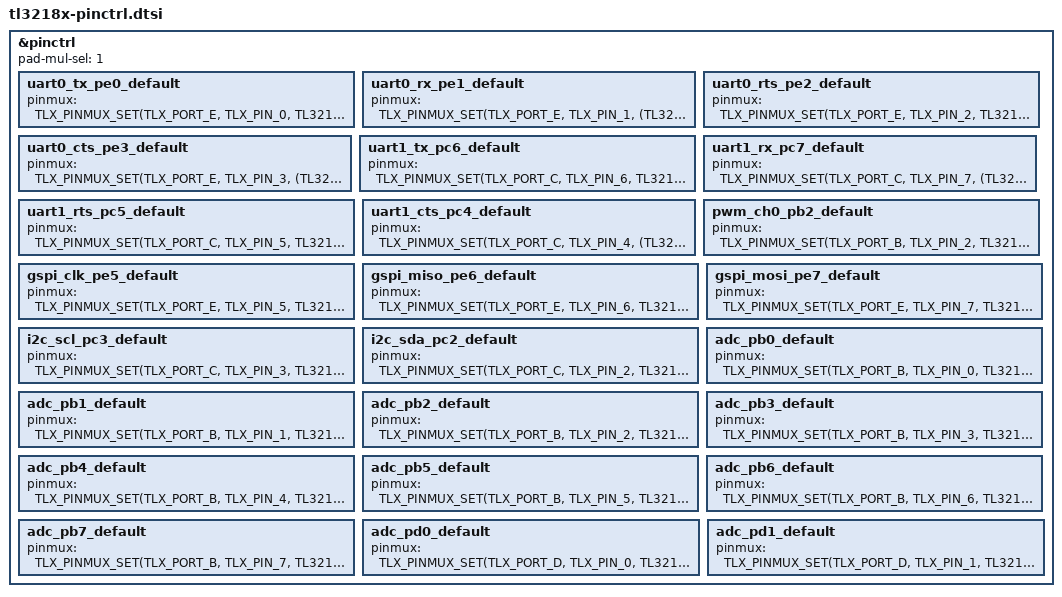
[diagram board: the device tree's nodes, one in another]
/*
 * Copyright (c) 2024 Telink Semiconductor
 *
 * SPDX-License-Identifier: Apache-2.0
 */

#include <zephyr/dt-bindings/pinctrl/tl321x-pinctrl.h>

&pinctrl {
	/* Set pad-mul-sel register value.
	 * Note: Pins functions below (pinmux = <...>) depend on this value.
	 */
	pad-mul-sel = <1>;

	/* UART0: TX(PE0), RX(PE1), RTS(PE2), CTS(PE3) */

	uart0_tx_pe0_default: uart0_tx_pe0_default {
		pinmux = <TLX_PINMUX_SET(TLX_PORT_E, TLX_PIN_0, TL321X_FUNC_UART0_TX)>;
	};
	uart0_rx_pe1_default: uart0_rx_pe1_default {
		pinmux = <TLX_PINMUX_SET(TLX_PORT_E, TLX_PIN_1,
				(TL321X_FUNC_UART0_RTX_IO | TL321X_PULL_UP))>;
	};
	uart0_rts_pe2_default: uart0_rts_pe2_default {
		pinmux = <TLX_PINMUX_SET(TLX_PORT_E, TLX_PIN_2, TL321X_FUNC_UART0_RTS)>;
	};
	uart0_cts_pe3_default: uart0_cts_pe3_default {
		pinmux = <TLX_PINMUX_SET(TLX_PORT_E, TLX_PIN_3,
				(TL321X_FUNC_UART0_CTS_I | TL321X_PULL_UP))>;
	};

	/* UART1: TX(PC6), RX(PC7), RTS(PC5), CTS(PC4) */

	uart1_tx_pc6_default: uart1_tx_pc6_default {
		pinmux = <TLX_PINMUX_SET(TLX_PORT_C, TLX_PIN_6, TL321X_FUNC_UART1_TX)>;
	};
	uart1_rx_pc7_default: uart1_rx_pc7_default {
		pinmux = <TLX_PINMUX_SET(TLX_PORT_C, TLX_PIN_7,
				(TL321X_FUNC_UART1_RTX_IO | TL321X_PULL_UP))>;
	};
	uart1_rts_pc5_default: uart1_rts_pc5_default {
		pinmux = <TLX_PINMUX_SET(TLX_PORT_C, TLX_PIN_5, TL321X_FUNC_UART1_RTS)>;
	};
	uart1_cts_pc4_default: uart1_cts_pc4_default {
		pinmux = <TLX_PINMUX_SET(TLX_PORT_C, TLX_PIN_4,
				(TL321X_FUNC_UART1_CTS_I | TL321X_PULL_UP))>;
	};

	/* PWM Channel 0 (PE4) */

	pwm_ch0_pb2_default: pwm_ch0_pb2_default {
		pinmux = <TLX_PINMUX_SET(TLX_PORT_B, TLX_PIN_2, TL321X_FUNC_PWM0)>;
	};

	/* Note:TL321X only supports gspi!!!*/
	/* GSPI: CLK(PE5), MISO(PE6), MOSI(PE7) */

	gspi_clk_pe5_default: gspi_clk_pe5_default {
		pinmux = <TLX_PINMUX_SET(TLX_PORT_E, TLX_PIN_5, TL321X_FUNC_GSPI_CK_IO)>;
	};
	gspi_miso_pe6_default: gspi_miso_pe6_default {
		pinmux = <TLX_PINMUX_SET(TLX_PORT_E, TLX_PIN_6, TL321X_FUNC_GSPI_MISO_IO)>;
	};
	gspi_mosi_pe7_default: gspi_mosi_pe7_default {
		pinmux = <TLX_PINMUX_SET(TLX_PORT_E, TLX_PIN_7, TL321X_FUNC_GSPI_MOSI_IO)>;
	};

	/* Define I2C pins: SCL(PC3), SDA(PC2) */

	i2c_scl_pc3_default: i2c_scl_pc3_default {
		pinmux = <TLX_PINMUX_SET(TLX_PORT_C, TLX_PIN_3, TL321X_FUNC_I2C_SCL_IO)>;
	};
	i2c_sda_pc2_default: i2c_sda_pc2_default {
		pinmux = <TLX_PINMUX_SET(TLX_PORT_C, TLX_PIN_2, TL321X_FUNC_I2C_SDA_IO)>;
	};

	/* Define ADC pins: PB0..PB7, PD0, PD1 */

	adc_pb0_default: adc_pb0_default {
		pinmux = <TLX_PINMUX_SET(TLX_PORT_B, TLX_PIN_0, TL321X_FUNC_DEFAULT)>;
	};
	adc_pb1_default: adc_pb1_default {
		pinmux = <TLX_PINMUX_SET(TLX_PORT_B, TLX_PIN_1, TL321X_FUNC_DEFAULT)>;
	};
	adc_pb2_default: adc_pb2_default {
		pinmux = <TLX_PINMUX_SET(TLX_PORT_B, TLX_PIN_2, TL321X_FUNC_DEFAULT)>;
	};
	adc_pb3_default: adc_pb3_default {
		pinmux = <TLX_PINMUX_SET(TLX_PORT_B, TLX_PIN_3, TL321X_FUNC_DEFAULT)>;
	};
	adc_pb4_default: adc_pb4_default {
		pinmux = <TLX_PINMUX_SET(TLX_PORT_B, TLX_PIN_4, TL321X_FUNC_DEFAULT)>;
	};
	adc_pb5_default: adc_pb5_default {
		pinmux = <TLX_PINMUX_SET(TLX_PORT_B, TLX_PIN_5, TL321X_FUNC_DEFAULT)>;
	};
	adc_pb6_default: adc_pb6_default {
		pinmux = <TLX_PINMUX_SET(TLX_PORT_B, TLX_PIN_6, TL321X_FUNC_DEFAULT)>;
	};
	adc_pb7_default: adc_pb7_default {
		pinmux = <TLX_PINMUX_SET(TLX_PORT_B, TLX_PIN_7, TL321X_FUNC_DEFAULT)>;
	};
	adc_pd0_default: adc_pd0_default {
		pinmux = <TLX_PINMUX_SET(TLX_PORT_D, TLX_PIN_0, TL321X_FUNC_DEFAULT)>;
	};
	adc_pd1_default: adc_pd1_default {
		pinmux = <TLX_PINMUX_SET(TLX_PORT_D, TLX_PIN_1, TL321X_FUNC_DEFAULT)>;
	};
};
